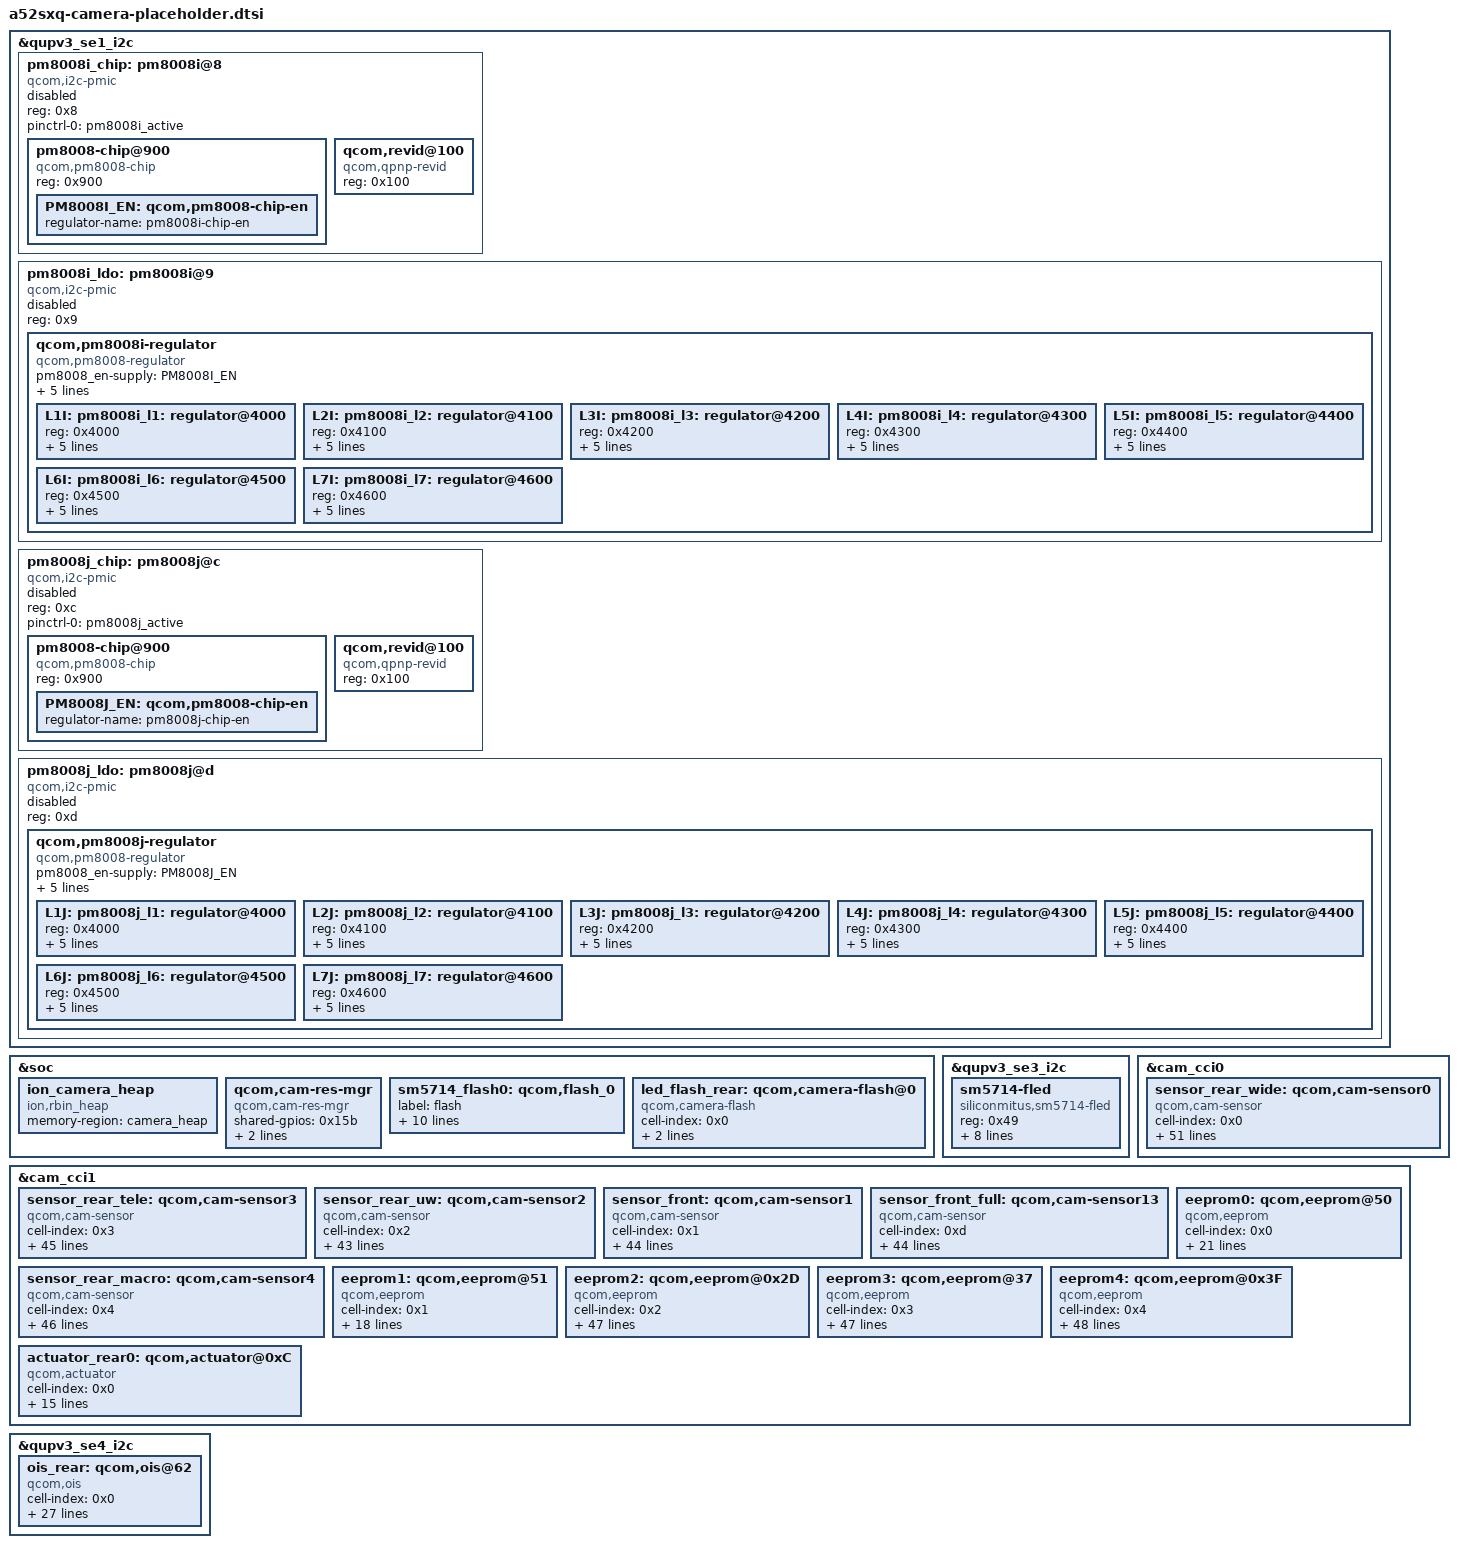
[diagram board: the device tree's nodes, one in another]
// SPDX-License-Identifier: GPL-2.0
/*
 * a52sxq board description for the Qualcomm 6.12 yupik base: camera (owned by agent 'camera': TODO-binding placeholder)
 * GENERATED by tools/gen.py from the phone's stock dtbo (5.4 bindings, values verbatim).
 * Do not edit: hand-written 6.12 changes live in a52sxq-bsp612-fixups.dtsi.
 */

&qupv3_se1_i2c {

	pm8008i_chip: pm8008i@8 {
		compatible = "qcom,i2c-pmic";
		reg = <0x8>;
		#address-cells = <0x1>;
		#size-cells = <0x0>;
		pinctrl-names = "default";
		pinctrl-0 = <&pm8008i_active>;
		status = "disabled";

		pm8008-chip@900 {
			compatible = "qcom,pm8008-chip";
			reg = <0x900>;

			PM8008I_EN: qcom,pm8008-chip-en {
				regulator-name = "pm8008i-chip-en";
			};
		};

		qcom,revid@100 {
			compatible = "qcom,qpnp-revid";
			reg = <0x100>;
		};
	};

	pm8008i_ldo: pm8008i@9 {
		compatible = "qcom,i2c-pmic";
		reg = <0x9>;
		#address-cells = <0x1>;
		#size-cells = <0x0>;
		status = "disabled";

		qcom,pm8008i-regulator {
			compatible = "qcom,pm8008-regulator";
			#address-cells = <0x1>;
			#size-cells = <0x0>;
			pm8008_en-supply = <&PM8008I_EN>;
			vdd_l1_l2-supply = <&S8B>;
			vdd_l3_l4-supply = <&BOB>;
			vdd_l5-supply = <&S1B>;
			vdd_l6-supply = <&BOB>;
			vdd_l7-supply = <&BOB>;

			L1I: pm8008i_l1: regulator@4000 {
				reg = <0x4000>;
				regulator-name = "pm8008i_l1";
				regulator-min-microvolt = <0xf4240>;
				regulator-max-microvolt = <0x124f80>;
				qcom,min-dropout-voltage = <0x27100>;
				qcom,hpm-min-load = <0x0>;
			};

			L2I: pm8008i_l2: regulator@4100 {
				reg = <0x4100>;
				regulator-name = "pm8008i_l2";
				regulator-min-microvolt = <0xe7ef0>;
				regulator-max-microvolt = <0x118c30>;
				qcom,min-dropout-voltage = <0x1f400>;
				qcom,hpm-min-load = <0x0>;
			};

			L3I: pm8008i_l3: regulator@4200 {
				reg = <0x4200>;
				regulator-name = "pm8008i_l3";
				regulator-min-microvolt = <0x2932e0>;
				regulator-max-microvolt = <0x2dc6c0>;
				qcom,min-dropout-voltage = <0x23280>;
				qcom,hpm-min-load = <0x0>;
			};

			L4I: pm8008i_l4: regulator@4300 {
				reg = <0x4300>;
				regulator-name = "pm8008i_l4";
				regulator-min-microvolt = <0x2932e0>;
				regulator-max-microvolt = <0x2c4020>;
				qcom,min-dropout-voltage = <0x1f400>;
				qcom,hpm-min-load = <0x0>;
			};

			L5I: pm8008i_l5: regulator@4400 {
				reg = <0x4400>;
				regulator-name = "pm8008i_l5";
				regulator-min-microvolt = <0x19f0a0>;
				regulator-max-microvolt = <0x1cfde0>;
				qcom,min-dropout-voltage = <0x21340>;
				qcom,hpm-min-load = <0x0>;
			};

			L6I: pm8008i_l6: regulator@4500 {
				reg = <0x4500>;
				regulator-name = "pm8008i_l6";
				regulator-min-microvolt = <0x2932e0>;
				regulator-max-microvolt = <0x2c4020>;
				qcom,min-dropout-voltage = <0x1f400>;
				qcom,hpm-min-load = <0x0>;
			};

			L7I: pm8008i_l7: regulator@4600 {
				reg = <0x4600>;
				regulator-name = "pm8008i_l7";
				regulator-min-microvolt = <0x2932e0>;
				regulator-max-microvolt = <0x2dc6c0>;
				qcom,min-dropout-voltage = <0x4c2c0>;
				qcom,hpm-min-load = <0x0>;
			};
		};
	};

	pm8008j_chip: pm8008j@c {
		compatible = "qcom,i2c-pmic";
		reg = <0xc>;
		#address-cells = <0x1>;
		#size-cells = <0x0>;
		pinctrl-names = "default";
		pinctrl-0 = <&pm8008j_active>;
		status = "disabled";

		pm8008-chip@900 {
			compatible = "qcom,pm8008-chip";
			reg = <0x900>;

			PM8008J_EN: qcom,pm8008-chip-en {
				regulator-name = "pm8008j-chip-en";
			};
		};

		qcom,revid@100 {
			compatible = "qcom,qpnp-revid";
			reg = <0x100>;
		};
	};

	pm8008j_ldo: pm8008j@d {
		compatible = "qcom,i2c-pmic";
		reg = <0xd>;
		#address-cells = <0x1>;
		#size-cells = <0x0>;
		status = "disabled";

		qcom,pm8008j-regulator {
			compatible = "qcom,pm8008-regulator";
			#address-cells = <0x1>;
			#size-cells = <0x0>;
			pm8008_en-supply = <&PM8008J_EN>;
			vdd_l1_l2-supply = <&S8B>;
			vdd_l3_l4-supply = <&S1B>;
			vdd_l5-supply = <&BOB>;
			vdd_l6-supply = <&BOB>;
			vdd_l7-supply = <&BOB>;

			L1J: pm8008j_l1: regulator@4000 {
				reg = <0x4000>;
				regulator-name = "pm8008j_l1";
				regulator-min-microvolt = <0xe7ef0>;
				regulator-max-microvolt = <0x118c30>;
				qcom,min-dropout-voltage = <0x17700>;
				qcom,hpm-min-load = <0x0>;
			};

			L2J: pm8008j_l2: regulator@4100 {
				reg = <0x4100>;
				regulator-name = "pm8008j_l2";
				regulator-min-microvolt = <0xe7ef0>;
				regulator-max-microvolt = <0x1312d0>;
				qcom,min-dropout-voltage = <0x5dc0>;
				qcom,hpm-min-load = <0x0>;
			};

			L3J: pm8008j_l3: regulator@4200 {
				reg = <0x4200>;
				regulator-name = "pm8008j_l3";
				regulator-min-microvolt = <0x164720>;
				regulator-max-microvolt = <0x1b7740>;
				qcom,min-dropout-voltage = <0x36b00>;
				qcom,hpm-min-load = <0x0>;
			};

			L4J: pm8008j_l4: regulator@4300 {
				reg = <0x4300>;
				regulator-name = "pm8008j_l4";
				regulator-min-microvolt = <0x16f300>;
				regulator-max-microvolt = <0x186a00>;
				qcom,min-dropout-voltage = <0x0>;
				qcom,hpm-min-load = <0x0>;
			};

			L5J: pm8008j_l5: regulator@4400 {
				reg = <0x4400>;
				regulator-name = "pm8008j_l5";
				regulator-min-microvolt = <0x2932e0>;
				regulator-max-microvolt = <0x2c4020>;
				qcom,min-dropout-voltage = <0x19640>;
				qcom,hpm-min-load = <0x0>;
			};

			L6J: pm8008j_l6: regulator@4500 {
				reg = <0x4500>;
				regulator-name = "pm8008j_l6";
				regulator-min-microvolt = <0x2ab980>;
				regulator-max-microvolt = <0x2ab980>;
				qcom,min-dropout-voltage = <0x1b580>;
				qcom,hpm-min-load = <0x0>;
			};

			L7J: pm8008j_l7: regulator@4600 {
				reg = <0x4600>;
				regulator-name = "pm8008j_l7";
				regulator-min-microvolt = <0x2dc6c0>;
				regulator-max-microvolt = <0x3613c0>;
				qcom,min-dropout-voltage = <0x17700>;
				qcom,hpm-min-load = <0x0>;
			};
		};
	};
};

&soc {

	ion_camera_heap {
		compatible = "ion,rbin_heap";
		memory-region = <&camera_heap>;
	};

	qcom,cam-res-mgr {
		compatible = "qcom,cam-res-mgr";
		shared-gpios = <0x15b>;
		pinctrl-names = "cam_res_mgr_default", "cam_res_mgr_suspend";
		status = "ok";
		pinctrl-0 = <&cam_sensor_active_vana0>;
		pinctrl-1 = <&cam_sensor_suspend_vana0>;
	};

	sm5714_flash0: qcom,flash_0 {
		label = "flash";
		qcom,led-name = "led:flash_0";
		qcom,max-current = <0x5dc>;
		qcom,default-led-trigger = "flash0_trigger";
		qcom,id = <0x0>;
		qcom,current-ma = <0x578>;
		qcom,duration-ms = <0x500>;
		qcom,ires-ua = <0x30d4>;
		qcom,hdrm-voltage-mv = <0x145>;
		qcom,hdrm-vol-hi-lo-win-mv = <0x64>;
		qcom,record-current-ma = <0x32>;
	};

	led_flash_rear: qcom,camera-flash@0 {
		cell-index = <0x0>;
		compatible = "qcom,camera-flash";
		flash-source = <&sm5714_flash0>;
		torch-source = <&sm5714_torch0>;
		status = "ok";
	};
};

&qupv3_se3_i2c {

	sm5714-fled {
		compatible = "siliconmitus,sm5714-fled";
		reg = <0x49>;
		status = "okay";
		slave-addr = <0x92>;
		flash-en-gpio = <&tlmm 0x60 0x0>;
		torch-en-gpio = <&tlmm 0x61 0x0>;
		flash-brightness = <0xf>;
		preflash-brightness = <0x7>;
		torch-brightness = <0x7>;
		factory_current = <0x0>;
		timeout = <0xff>;
	};
};

&cam_cci0 {	/* TODO-binding: label not in the 6.12 base, placeholder */

	sensor_rear_wide: qcom,cam-sensor0 {
		cell-index = <0x0>;
		compatible = "qcom,cam-sensor";
		csiphy-sd-index = <0x0>;
		sensor-position-roll = <0x5a>;
		sensor-position-pitch = <0x0>;
		sensor-position-yaw = <0xb4>;
		actuator-src = <&actuator_rear0>;
		eeprom-src = <&eeprom0>;
		ois-src = <&ois_rear>;
		led-flash-src = <&led_flash_rear>;
		cam_vdig-supply = <&s2mpb03_0_l2>;
		cam_vio-supply = <&s2mpb03_0_l3>;
		cam_vana-supply = <&s2mpb03_0_l5>;
		cam_vaf-supply = <&s2mpb03_0_l7>;
		cam_clk-supply = <&cam_cc_titan_top_gdsc>;
		regulator-names = "cam_vdig", "cam_vio", "cam_vana", "cam_vaf", "cam_clk";
		rgltr-cntrl-support;
		rgltr-min-voltage = <0x10c8e0 0x1b7740 0x2ab980 0x2ab980 0x0>;
		rgltr-max-voltage = <0x10c8e0 0x1b7740 0x2ab980 0x2ab980 0x0>;
		rgltr-load-current = <0x30d40 0x30d40 0x1388 0x30d40 0x0>;
		gpio-no-mux = <0x0>;
		use-shared-clk;
		pinctrl-names = "cam_default", "cam_suspend";
		pinctrl-0 = <&cam_sensor_active_mclk0 &cam_sensor_active_rst0 &cam_flash_active>;
		pinctrl-1 = <&cam_sensor_suspend_mclk0 &cam_sensor_suspend_rst0 &cam_flash_suspend>;
		gpios = <&tlmm 0x40 0x0 &tlmm 0x14 0x0 &tlmm 0xb 0x0>;
		gpio-reset = <0x1>;
		gpio-vana = <0x2>;
		gpio-req-tbl-num = <0x0 0x1 0x2>;
		gpio-req-tbl-flags = <0x1 0x0 0x0>;
		gpio-req-tbl-label = "CAMIF_MCLK0", "CAM_RESET0", "CAM_VANA0";
		sensor-mode = <0x0>;
		cci-master = <0x0>;
		status = "ok";
		clocks = <&camcc 0x5c>;
		clock-names = "cam_clk";
		clock-cntl-level = "turbo";
		clock-rates = <0x124f800>;
		cam,isp = <0x0>;
		cam,cal_memory = <0x2>;
		cam,read_version = <0x1>;
		cam,core_voltage = <0x1>;
		cam,upgrade = <0x2>;
		cam,fw_write = <0x3>;
		cam,fw_dump = <0x1>;
		cam,companion_chip = <0x0>;
		cam,ois = <0x1>;
		cam,dual_open = <0x0>;
		cam,valid = <0x1>;
	};
};

&cam_cci1 {	/* TODO-binding: label not in the 6.12 base, placeholder */

	sensor_rear_tele: qcom,cam-sensor3 {
		cell-index = <0x3>;
		compatible = "qcom,cam-sensor";
		csiphy-sd-index = <0x1>;
		sensor-position-roll = <0x5a>;
		sensor-position-pitch = <0x0>;
		sensor-position-yaw = <0xb4>;
		eeprom-src = <&eeprom3>;
		cam_vdig-supply = <&s2mpb03_0_l4>;
		cam_vio-supply = <&s2mpb03_0_l3>;
		cam_clk-supply = <&cam_cc_titan_top_gdsc>;
		regulator-names = "cam_vdig", "cam_vio", "cam_clk";
		rgltr-cntrl-support;
		rgltr-min-voltage = <0x124f80 0x1b7740 0x0>;
		rgltr-max-voltage = <0x124f80 0x1b7740 0x0>;
		rgltr-load-current = <0x30d40 0x30d40 0x0>;
		gpio-no-mux = <0x0>;
		use-shared-clk;
		pinctrl-names = "cam_default", "cam_suspend";
		pinctrl-0 = <&cam_sensor_active_mclk1 &cam_sensor_active_rst1 &cam_sensor_active_vana1>;
		pinctrl-1 = <&cam_sensor_suspend_mclk1 &cam_sensor_suspend_rst1 &cam_sensor_suspend_vana1>;
		gpios = <&tlmm 0x41 0x0 &tlmm 0x15 0x0 &tlmm 0xe 0x0>;
		gpio-reset = <0x1>;
		gpio-vana = <0x2>;
		gpio-req-tbl-num = <0x0 0x1 0x2>;
		gpio-req-tbl-flags = <0x1 0x0 0x0>;
		gpio-req-tbl-label = "CAMIF_MCLK1", "CAM_RESET1", "CAM_VANA1";
		sensor-mode = <0x0>;
		cci-device = <0x1>;
		cci-master = <0x0>;
		status = "ok";
		clocks = <&camcc 0x5e>;
		clock-names = "cam_clk";
		clock-cntl-level = "turbo";
		clock-rates = <0x16e3600>;
		cam,isp = <0x0>;
		cam,cal_memory = <0x2>;
		cam,read_version = <0x0>;
		cam,core_voltage = <0x0>;
		cam,upgrade = <0x0>;
		cam,fw_write = <0x0>;
		cam,fw_dump = <0x0>;
		cam,companion_chip = <0x0>;
		cam,ois = <0x0>;
		cam,dual_open = <0x0>;
		cam,valid = <0x1>;
	};

	sensor_rear_uw: qcom,cam-sensor2 {
		cell-index = <0x2>;
		compatible = "qcom,cam-sensor";
		csiphy-sd-index = <0x2>;
		sensor-position-roll = <0x5a>;
		sensor-position-pitch = <0x0>;
		sensor-position-yaw = <0xb4>;
		eeprom-src = <&eeprom2>;
		cam_vio-supply = <&s2mpb03_0_l3>;
		cam_clk-supply = <&cam_cc_titan_top_gdsc>;
		regulator-names = "cam_vio", "cam_clk";
		rgltr-cntrl-support;
		rgltr-min-voltage = <0x1b7740 0x0>;
		rgltr-max-voltage = <0x1b7740 0x0>;
		rgltr-load-current = <0x30d40 0x0>;
		gpio-no-mux = <0x0>;
		pinctrl-names = "cam_default", "cam_suspend";
		pinctrl-0 = <&cam_sensor_active_mclk2 &cam_sensor_active_rst2 &cam_sensor_active_vana2>;
		pinctrl-1 = <&cam_sensor_suspend_mclk2 &cam_sensor_suspend_rst2 &cam_sensor_suspend_vana2>;
		gpios = <&tlmm 0x42 0x0 &tlmm 0x4d 0x0 &tlmm 0xf 0x0>;
		gpio-reset = <0x1>;
		gpio-vana = <0x2>;
		gpio-req-tbl-num = <0x0 0x1 0x2>;
		gpio-req-tbl-flags = <0x1 0x0 0x0>;
		gpio-req-tbl-label = "CAMIF_MCLK2", "CAM_RESET2", "CAM_VANA2";
		sensor-mode = <0x0>;
		cci-device = <0x1>;
		cci-master = <0x0>;
		status = "ok";
		clocks = <&camcc 0x60>;
		clock-names = "cam_clk";
		clock-cntl-level = "turbo";
		clock-rates = <0x124f800>;
		cam,isp = <0x0>;
		cam,cal_memory = <0x2>;
		cam,read_version = <0x0>;
		cam,core_voltage = <0x0>;
		cam,upgrade = <0x0>;
		cam,fw_write = <0x0>;
		cam,fw_dump = <0x0>;
		cam,companion_chip = <0x0>;
		cam,ois = <0x0>;
		cam,dual_open = <0x0>;
		cam,valid = <0x1>;
	};

	sensor_front: qcom,cam-sensor1 {
		cell-index = <0x1>;
		compatible = "qcom,cam-sensor";
		csiphy-sd-index = <0x4>;
		sensor-position-roll = <0x10e>;
		sensor-position-pitch = <0x0>;
		sensor-position-yaw = <0x0>;
		eeprom-src = <&eeprom1>;
		cam_vdig-supply = <&s2mpb03_0_l1>;
		cam_vio-supply = <&s2mpb03_0_l3>;
		cam_vana-supply = <&s2mpb03_0_l6>;
		cam_clk-supply = <&cam_cc_titan_top_gdsc>;
		regulator-names = "cam_vdig", "cam_vio", "cam_vana", "cam_clk";
		rgltr-cntrl-support;
		rgltr-min-voltage = <0x100590 0x1b7740 0x2c4020 0x0>;
		rgltr-max-voltage = <0x100590 0x1b7740 0x2c4020 0x0>;
		rgltr-load-current = <0x30d40 0x30d40 0x1388 0x0>;
		gpio-no-mux = <0x0>;
		pinctrl-names = "cam_default", "cam_suspend";
		pinctrl-0 = <&cam_sensor_active_mclk3 &cam_sensor_active_rst3>;
		pinctrl-1 = <&cam_sensor_suspend_mclk3 &cam_sensor_suspend_rst3>;
		gpios = <&tlmm 0x44 0x0 &tlmm 0x4f 0x0>;
		gpio-reset = <0x1>;
		gpio-req-tbl-num = <0x0 0x1>;
		gpio-req-tbl-flags = <0x1 0x0>;
		gpio-req-tbl-label = "CAMIF_MCLK4", "CAM_RESET4";
		sensor-mode = <0x0>;
		cci-device = <0x1>;
		cci-master = <0x0>;
		status = "ok";
		clocks = <&camcc 0x64>;
		clock-names = "cam_clk";
		clock-cntl-level = "turbo";
		clock-rates = <0x16e3600>;
		cam,isp = <0x0>;
		cam,cal_memory = <0x2>;
		cam,read_version = <0x0>;
		cam,core_voltage = <0x0>;
		cam,upgrade = <0x0>;
		cam,fw_write = <0x0>;
		cam,fw_dump = <0x0>;
		cam,companion_chip = <0x0>;
		cam,ois = <0x0>;
		cam,dual_open = <0x0>;
		cam,valid = <0x1>;
	};

	sensor_front_full: qcom,cam-sensor13 {
		cell-index = <0xd>;
		compatible = "qcom,cam-sensor";
		csiphy-sd-index = <0x4>;
		sensor-position-roll = <0x10e>;
		sensor-position-pitch = <0x0>;
		sensor-position-yaw = <0x0>;
		eeprom-src = <&eeprom1>;
		cam_vdig-supply = <&s2mpb03_0_l1>;
		cam_vio-supply = <&s2mpb03_0_l3>;
		cam_vana-supply = <&s2mpb03_0_l6>;
		cam_clk-supply = <&cam_cc_titan_top_gdsc>;
		regulator-names = "cam_vdig", "cam_vio", "cam_vana", "cam_clk";
		rgltr-cntrl-support;
		rgltr-min-voltage = <0x100590 0x1b7740 0x2c4020 0x0>;
		rgltr-max-voltage = <0x100590 0x1b7740 0x2c4020 0x0>;
		rgltr-load-current = <0x30d40 0x30d40 0x1388 0x0>;
		gpio-no-mux = <0x0>;
		pinctrl-names = "cam_default", "cam_suspend";
		pinctrl-0 = <&cam_sensor_active_mclk3 &cam_sensor_active_rst3>;
		pinctrl-1 = <&cam_sensor_suspend_mclk3 &cam_sensor_suspend_rst3>;
		gpios = <&tlmm 0x44 0x0 &tlmm 0x4f 0x0>;
		gpio-reset = <0x1>;
		gpio-req-tbl-num = <0x0 0x1>;
		gpio-req-tbl-flags = <0x1 0x0>;
		gpio-req-tbl-label = "CAMIF_MCLK4", "CAM_RESET4";
		sensor-mode = <0x0>;
		cci-device = <0x1>;
		cci-master = <0x0>;
		status = "ok";
		clocks = <&camcc 0x64>;
		clock-names = "cam_clk";
		clock-cntl-level = "turbo";
		clock-rates = <0x16e3600>;
		cam,isp = <0x0>;
		cam,cal_memory = <0x2>;
		cam,read_version = <0x0>;
		cam,core_voltage = <0x0>;
		cam,upgrade = <0x0>;
		cam,fw_write = <0x0>;
		cam,fw_dump = <0x0>;
		cam,companion_chip = <0x0>;
		cam,ois = <0x0>;
		cam,dual_open = <0x0>;
		cam,valid = <0x1>;
	};

	sensor_rear_macro: qcom,cam-sensor4 {
		cell-index = <0x4>;
		compatible = "qcom,cam-sensor";
		csiphy-sd-index = <0x3>;
		sensor-position-roll = <0x5a>;
		sensor-position-pitch = <0x0>;
		sensor-position-yaw = <0xb4>;
		led-flash-src = <&led_flash_rear>;
		eeprom-src = <&eeprom4>;
		cam_vdig-supply = <&s2mpb03_0_l4>;
		cam_vio-supply = <&s2mpb03_0_l3>;
		cam_clk-supply = <&cam_cc_titan_top_gdsc>;
		regulator-names = "cam_vdig", "cam_vio", "cam_clk";
		rgltr-cntrl-support;
		rgltr-min-voltage = <0x124f80 0x1b7740 0x0>;
		rgltr-max-voltage = <0x124f80 0x1b7740 0x0>;
		rgltr-load-current = <0x30d40 0x30d40 0x0>;
		gpio-no-mux = <0x0>;
		use-shared-clk;
		pinctrl-names = "cam_default", "cam_suspend";
		pinctrl-0 = <&cam_sensor_active_mclk4 &cam_sensor_active_rst4 &cam_sensor_active_vana1 &cam_flash_active>;
		pinctrl-1 = <&cam_sensor_suspend_mclk4 &cam_sensor_suspend_rst4 &cam_sensor_suspend_vana1 &cam_flash_suspend>;
		gpios = <&tlmm 0x43 0x0 &tlmm 0x4e 0x0 &tlmm 0xe 0x0>;
		gpio-reset = <0x1>;
		gpio-vana = <0x2>;
		gpio-req-tbl-num = <0x0 0x1 0x2>;
		gpio-req-tbl-flags = <0x1 0x0 0x0>;
		gpio-req-tbl-label = "CAMIF_MCLK3", "CAM_RESET3", "CAM_VANA1";
		sensor-mode = <0x0>;
		cci-device = <0x1>;
		cci-master = <0x0>;
		status = "ok";
		clocks = <&camcc 0x62>;
		clock-names = "cam_clk";
		clock-cntl-level = "turbo";
		clock-rates = <0x16e3600>;
		cam,isp = <0x0>;
		cam,cal_memory = <0x2>;
		cam,read_version = <0x0>;
		cam,core_voltage = <0x0>;
		cam,upgrade = <0x0>;
		cam,fw_write = <0x0>;
		cam,fw_dump = <0x0>;
		cam,companion_chip = <0x0>;
		cam,ois = <0x0>;
		cam,dual_open = <0x0>;
		cam,valid = <0x1>;
	};

	eeprom0: qcom,eeprom@50 {
		cell-index = <0x0>;
		reg = <0x50>;
		compatible = "qcom,eeprom";
		i2c-freq-mode = <0x1>;
		cam_vaf-supply = <&s2mpb03_0_l7>;
		cam_vio-supply = <&s2mpb03_0_l3>;
		regulator-names = "cam_vaf", "cam_vio";
		rgltr-cntrl-support;
		slave-addr = <0xa0>;
		sensor-mode = <0x0>;
		cci-device = <0x1>;
		cci-master = <0x1>;
		sub-type = <0x2>;
		qcom,cam-power-seq-type = "sensor_vreg", "sensor_vreg";
		qcom,cam-power-seq-val = "cam_vaf", "cam_vio";
		qcom,cam-power-seq-cfg-val = <0x1 0x1>;
		qcom,cam-power-seq-delay = <0x2 0x2>;
		rgltr-min-voltage = <0x2ab980 0x1b7740>;
		rgltr-max-voltage = <0x2ab980 0x1b7740>;
		rgltr-load-current = <0x30d40 0x30d40>;
		sensor-position = <0x0>;
		gpio-no-mux = <0x0>;
	};

	eeprom1: qcom,eeprom@51 {
		cell-index = <0x1>;
		reg = <0x51>;
		compatible = "qcom,eeprom";
		i2c-freq-mode = <0x1>;
		slave-addr = <0xa2>;
		sensor-mode = <0x1>;
		cci-device = <0x1>;
		cci-master = <0x1>;
		sub-type = <0x2>;
		qcom,cam-power-seq-type = "sensor_vreg";
		qcom,cam-power-seq-val = "cam_vio";
		qcom,cam-power-seq-cfg-val = <0x1>;
		qcom,cam-power-seq-delay = <0x2>;
		cam_vio-supply = <&s2mpb03_0_l3>;
		regulator-names = "cam_vio";
		rgltr-min-voltage = <0x1b7740>;
		rgltr-max-voltage = <0x1b7740>;
		rgltr-load-current = <0x30d40>;
		sensor-position = <0x1>;
		rgltr-cntrl-support;
	};

	eeprom2: qcom,eeprom@0x2D {
		cell-index = <0x2>;
		reg = <0x2d>;
		slave-addr = <0x5a>;
		compatible = "qcom,eeprom";
		i2c-freq-mode = <0x1>;
		csiphy-sd-index = <0x2>;
		sensor-position-roll = <0x5a>;
		sensor-position-pitch = <0x0>;
		sensor-position-yaw = <0xb4>;
		sub-type = <0x2>;
		cam_vio-supply = <&s2mpb03_0_l3>;
		cam_clk-supply = <&cam_cc_titan_top_gdsc>;
		regulator-names = "cam_vio", "cam_clk";
		rgltr-cntrl-support;
		rgltr-min-voltage = <0x1b7740 0x0>;
		rgltr-max-voltage = <0x1b7740 0x0>;
		rgltr-load-current = <0x30d40 0x0>;
		gpio-no-mux = <0x0>;
		use-shared-clk;
		pinctrl-names = "cam_default", "cam_suspend";
		pinctrl-0 = <&cam_sensor_active_mclk2 &cam_sensor_active_rst2 &cam_sensor_active_vana2>;
		pinctrl-1 = <&cam_sensor_suspend_mclk2 &cam_sensor_suspend_rst2 &cam_sensor_suspend_vana2>;
		gpios = <&tlmm 0x42 0x0 &tlmm 0x4d 0x0 &tlmm 0xf 0x0>;
		gpio-reset = <0x1>;
		gpio-vana = <0x2>;
		gpio-req-tbl-num = <0x0 0x1 0x2>;
		gpio-req-tbl-flags = <0x1 0x0 0x0>;
		gpio-req-tbl-label = "CAMIF_MCLK2", "CAM_RESET2", "CAM_VANA2";
		sensor-mode = <0x0>;
		cci-device = <0x1>;
		cci-master = <0x0>;
		status = "ok";
		clocks = <&camcc 0x60>;
		clock-names = "cam_clk";
		clock-cntl-level = "turbo";
		clock-rates = <0x16e3600>;
		cam,isp = <0x0>;
		cam,cal_memory = <0x2>;
		cam,read_version = <0x1>;
		cam,core_voltage = <0x1>;
		cam,upgrade = <0x2>;
		cam,fw_write = <0x3>;
		cam,fw_dump = <0x1>;
		cam,companion_chip = <0x0>;
		cam,ois = <0x0>;
		cam,dual_open = <0x0>;
		cam,valid = <0x1>;
	};

	eeprom3: qcom,eeprom@37 {
		cell-index = <0x3>;
		reg = <0x37>;
		compatible = "qcom,eeprom";
		i2c-freq-mode = <0x1>;
		slave-addr = <0x6e>;
		csiphy-sd-index = <0x1>;
		sensor-position-roll = <0x5a>;
		sensor-position-pitch = <0x0>;
		sensor-position-yaw = <0xb4>;
		sub-type = <0x2>;
		cam_vio-supply = <&s2mpb03_0_l3>;
		cam_vdig-supply = <&s2mpb03_0_l4>;
		cam_clk-supply = <&cam_cc_titan_top_gdsc>;
		regulator-names = "cam_vio", "cam_vdig", "cam_clk";
		rgltr-cntrl-support;
		rgltr-min-voltage = <0x1b7740 0x124f80 0x0>;
		rgltr-max-voltage = <0x1b7740 0x124f80 0x0>;
		rgltr-load-current = <0x30d40 0x30d40 0x0>;
		gpio-no-mux = <0x0>;
		pinctrl-names = "cam_default", "cam_suspend";
		pinctrl-0 = <&cam_sensor_active_mclk1 &cam_sensor_active_rst1 &cam_sensor_active_vana1>;
		pinctrl-1 = <&cam_sensor_suspend_mclk1 &cam_sensor_suspend_rst1 &cam_sensor_suspend_vana1>;
		gpios = <&tlmm 0x41 0x0 &tlmm 0x15 0x0 &tlmm 0xe 0x0>;
		gpio-reset = <0x1>;
		gpio-vana = <0x2>;
		gpio-req-tbl-num = <0x0 0x1 0x2>;
		gpio-req-tbl-flags = <0x1 0x0 0x0>;
		gpio-req-tbl-label = "CAMIF_MCLK1", "CAM_RESET1", "CAM_VANA1";
		sensor-mode = <0x0>;
		cci-device = <0x1>;
		cci-master = <0x0>;
		status = "ok";
		clocks = <&camcc 0x5e>;
		clock-names = "cam_clk";
		clock-cntl-level = "turbo";
		clock-rates = <0x16e3600>;
		cam,isp = <0x0>;
		cam,cal_memory = <0x2>;
		cam,read_version = <0x1>;
		cam,core_voltage = <0x1>;
		cam,upgrade = <0x2>;
		cam,fw_write = <0x3>;
		cam,fw_dump = <0x1>;
		cam,companion_chip = <0x0>;
		cam,ois = <0x0>;
		cam,dual_open = <0x0>;
		cam,valid = <0x1>;
	};

	eeprom4: qcom,eeprom@0x3F {
		cell-index = <0x4>;
		reg = <0x3f>;
		slave-addr = <0x7e>;
		compatible = "qcom,eeprom";
		i2c-freq-mode = <0x1>;
		sub-type = <0x2>;
		csiphy-sd-index = <0x2>;
		sensor-position-roll = <0x5a>;
		sensor-position-pitch = <0x0>;
		sensor-position-yaw = <0xb4>;
		cam_vdig-supply = <&s2mpb03_0_l4>;
		cam_vio-supply = <&s2mpb03_0_l3>;
		cam_clk-supply = <&cam_cc_titan_top_gdsc>;
		regulator-names = "cam_vdig", "cam_vio", "cam_clk";
		rgltr-cntrl-support;
		rgltr-min-voltage = <0x124f80 0x1b7740 0x0>;
		rgltr-max-voltage = <0x124f80 0x1b7740 0x0>;
		rgltr-load-current = <0x30d40 0x30d40 0x0>;
		gpio-no-mux = <0x0>;
		use-shared-clk;
		pinctrl-names = "cam_default", "cam_suspend";
		pinctrl-0 = <&cam_sensor_active_mclk4 &cam_sensor_active_rst4 &cam_sensor_active_vana1>;
		pinctrl-1 = <&cam_sensor_suspend_mclk4 &cam_sensor_suspend_rst4 &cam_sensor_suspend_vana1>;
		gpios = <&tlmm 0x43 0x0 &tlmm 0x4e 0x0 &tlmm 0xe 0x0>;
		gpio-reset = <0x1>;
		gpio-vana = <0x2>;
		gpio-req-tbl-num = <0x0 0x1 0x2>;
		gpio-req-tbl-flags = <0x1 0x0 0x0>;
		gpio-req-tbl-label = "CAMIF_MCLK3", "CAM_RESET3", "CAM_VANA1";
		sensor-mode = <0x0>;
		cci-device = <0x1>;
		cci-master = <0x0>;
		status = "ok";
		clocks = <&camcc 0x62>;
		clock-names = "cam_clk";
		clock-cntl-level = "turbo";
		clock-rates = <0x16e3600>;
		cam,isp = <0x0>;
		cam,cal_memory = <0x2>;
		cam,read_version = <0x1>;
		cam,core_voltage = <0x1>;
		cam,upgrade = <0x2>;
		cam,fw_write = <0x3>;
		cam,fw_dump = <0x1>;
		cam,companion_chip = <0x0>;
		cam,ois = <0x0>;
		cam,dual_open = <0x0>;
		cam,valid = <0x1>;
	};

	actuator_rear0: qcom,actuator@0xC {
		cell-index = <0x0>;
		reg = <0xc>;
		slave-addr = <0x18>;
		cci-device = <0x1>;
		cci-master = <0x1>;
		compatible = "qcom,actuator";
		i2c-freq-mode = <0x3>;
		cam_vio-supply = <&s2mpb03_0_l3>;
		cam_vaf-supply = <&s2mpb03_0_l7>;
		regulator-names = "cam_vio", "cam_vaf";
		rgltr-cntrl-support;
		rgltr-min-voltage = <0x1b7740 0x2ab980>;
		rgltr-max-voltage = <0x1b7740 0x2ab980>;
		rgltr-load-current = <0x30d40 0x30d40>;
		qcom,cam-power-seq-type = "cam_vio", "cam_vaf";
		qcom,cam-power-seq-cfg-val = <0x1 0x1>;
		qcom,cam-power-seq-delay = <0x1 0xc>;
	};
};

&qupv3_se4_i2c {

	ois_rear: qcom,ois@62 {
		compatible = "qcom,ois";
		cell-index = <0x0>;
		reg = <0x51>;
		slave-addr = <0xc4>;
		slave-id = <0x456>;
		pole-values = <0x0 0x1 0x0 0x0 0x0 0x0>;
		gyro-orientation = <0x0>;
		cam_vio-supply = <&pm8350c_l2>;
		cam_vaf-supply = <&s2mpb03_0_l7>;
		regulator-names = "cam_vio", "cam_vaf";
		rgltr-cntrl-support;
		rgltr-min-voltage = <0x1b7740 0x2ab980>;
		rgltr-max-voltage = <0x1b7740 0x2ab980>;
		rgltr-load-current = <0x30d40 0x30d40>;
		qcom,cam-power-seq-type = "cam_vana", "cam_vaf", "cam_vio", "cam_reset";
		qcom,cam-power-seq-cfg-val = <0x1 0x1 0x1 0x1>;
		qcom,cam-power-seq-delay = <0x1 0x1 0x1 0xa>;
		pinctrl-names = "cam_default", "cam_suspend";
		pinctrl-0 = <&mcu_active>;
		pinctrl-1 = <&mcu_suspend>;
		gpio-no-mux = <0x0>;
		gpios = <&tlmm 0x2d 0x0 &tlmm 0xb 0x0 &tlmm 0x2e 0x0>;
		gpio-reset = <0x0>;
		gpio-vana = <0x1>;
		gpio-custom1 = <0x2>;
		gpio-req-tbl-num = <0x0 0x1 0x2>;
		gpio-req-tbl-flags = <0x0 0x0 0x0>;
		gpio-req-tbl-label = "MCU_RESET0", "MCU_VANA", "MCU_BOOT0";
		status = "ok";
	};
};

